# CC2340R5 register map
File version: 1.0
CPU: CM0P 1.0, other endian, MPU, FPU, 3 interrupt priority bits
Registers are 32-bit, read-write, reset 0x0 unless marked. A register's access mark holds for its fields unless they carry their own. Offsets are from the block's base; [hi:lo] are bit positions; {n}, {i} and the like mark numbered series.

## CLKCTL — This component is the clock controller. Here SW can turn on and off IP clocks and read IP and system clock status.
Base 0x40020000
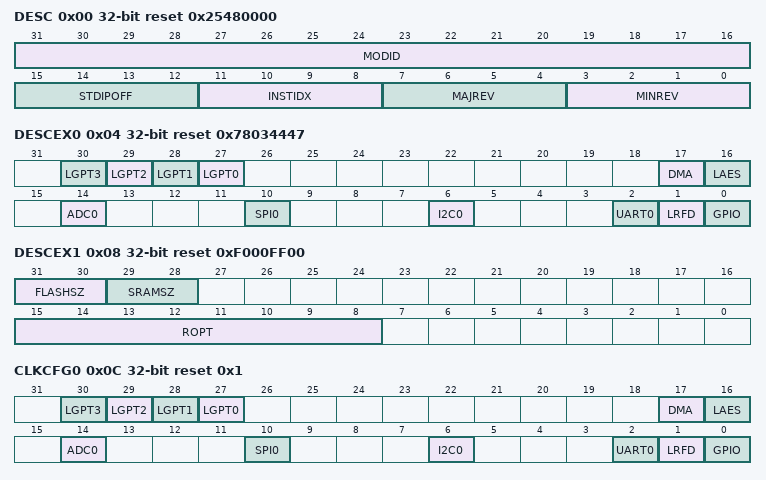
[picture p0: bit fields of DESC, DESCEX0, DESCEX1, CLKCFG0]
0x00 DESC reset 0x25480000 — Description Register. This register provides IP module ID, revision information, instance index and standard MMR registers offset.
  [31:16] MODID ro — [31:16] Module identifier used to uniquely identify this IP.
  [15:12] STDIPOFF ro — [15:12] Standard IP MMR block offset. Standard IP MMRs are the set of from aggregated IRQ registers till DTB. 0: Standard IP MMRs do not exist 0x1-0xF: Standard IP MMRs begin at offset of (64*STDIPOFF from the base IP address)
  [11:8] INSTIDX ro — [11:8] IP Instance ID number. If multiple instances of IP exist in the device, this field can identify the instance number (0-15).
  [7:4] MAJREV ro — [7:4] Major revision of IP 0-15
  [3:0] MINREV ro — [3:0] Minor revision of IP 0-15.
0x04 DESCEX0 reset 0x78034447 — Extended Description Register 0. This register shows SVT IP availability, HW features and memory size configuration.
  [all] fields
    1=IP_AVAIL (IP is available); 0=IP_UNAVAIL (IP is unavailable)
  [n+27] LGPT{n} ro (n=0..3) — [{n+27}:{n+27}] IP status on device
  [17] DMA ro — [17:17] IP status on device
  [16] LAES ro — [16:16] IP status on device
  [14] ADC0 ro — [14:14] IP status on device
  [10] SPI0 ro — [10:10] IP status on device
  [6] I2C0 ro — [6:6] IP status on device
  [2] UART0 ro — [2:2] IP status on device
  [1] LRFD ro — [1:1] IP status on device
  [0] GPIO ro — [0:0] IP status on device
0x08 DESCEX1 reset 0xF000FF00 — Extended Description Register 1. This register shows SVT IP availability, HW features and memory size configuration.
  [31:30] FLASHSZ ro — [31:30] System flash availability
    3=SZ3 (Flash size set to level 3 (Max size)); 2=SZ2 (Flash size set to level 2); 1=SZ1 (Flash size set to level 1); 0=SZ0 (Flash size set to level 0 (Min size))
  [29:28] SRAMSZ ro — [29:28] System SRAM availability
    3=SZ3 (SRAM size set to level 3 (Max size)); 2=SZ2 (SRAM size set to level 2); 1=SZ1 (SRAM size set to level 1); 0=SZ0 (SRAM size set to level 0 (Min size))
  [15:8] ROPT ro — [15:8] System radio feature availability
    255=MAX (All features available)
0x0C CLKCFG0 reset 0x1 — Clock Configuration Register 0. This register shows the IP clock configuration for the system. The configuration is updated through CLKENSET0 and CLKENCLR0.
  [all] fields
    1=CLK_EN (Clock is enabled); 0=CLK_DIS (Clock is disabled)
  [n+27] LGPT{n} ro (n=0..3) — [{n+27}:{n+27}] IP clock configuration
  [17] DMA ro — [17:17] IP clock configuration
  [16] LAES ro — [16:16] IP clock configuration
  [14] ADC0 ro — [14:14] IP clock configuration
  [10] SPI0 ro — [10:10] IP clock configuration
  [6] I2C0 ro — [6:6] IP clock configuration
  [2] UART0 ro — [2:2] IP clock configuration
  [1] LRFD ro — [1:1] IP clock configuration
  [0] GPIO ro — [0:0] IP clock configuration
0x10 CLKCFG1 — Clock Configuration Register 1. This register shows the IP clock configuration for the system. The configuration is updated through CLKENSET1 and CLKENCLR1.
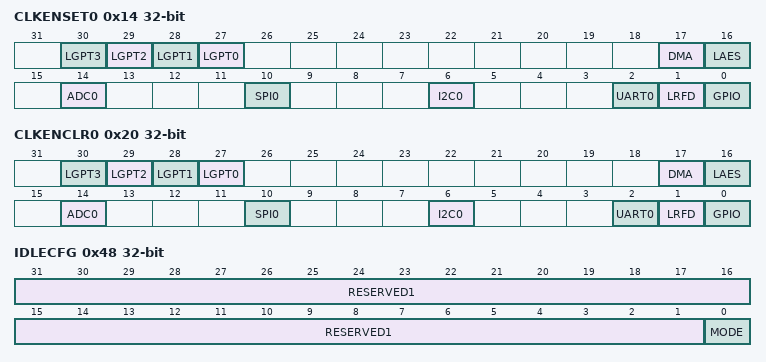
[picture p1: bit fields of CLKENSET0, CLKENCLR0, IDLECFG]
0x14 CLKENSET0 — Clock Enable Set Register 0. This register enables IP clocks in the system. Used to set the corresponding fields in CLKCFG0 to 1.
  [all] fields
    1=CLK_SET (Set IP clock enable); 0=CLK_UNCHGD (IP clock enable is unchanged)
  [n+27] LGPT{n} wo (n=0..3) — [{n+27}:{n+27}] Configure IP clock enable
  [17] DMA wo — [17:17] Configure IP clock enable
  [16] LAES wo — [16:16] Configure IP clock enable
  [14] ADC0 wo — [14:14] Configure IP clock enable
  [10] SPI0 wo — [10:10] Configure IP clock enable
  [6] I2C0 wo — [6:6] Configure IP clock enable
  [2] UART0 wo — [2:2] Configure IP clock enable
  [1] LRFD wo — [1:1] Configure IP clock enable
  [0] GPIO wo — [0:0] Configure IP clock enable
0x18 CLKENSET1 — Clock Enable Set Register 1. This register enables IP clocks in the system. Used to set the corresponding fields in CLKCFG1 to 1.
0x20 CLKENCLR0 — Clock Enable Clear Register 0. This register disables IP clocks in the system. Used to clear the corresponding fields in CLKCFG0 to 0.
  [all] fields
    1=CLK_CLR (Clear IP clock enable); 0=CLK_UNCHGD (IP clock enable is unchanged)
  [n+27] LGPT{n} wo (n=0..3) — [{n+27}:{n+27}] Configure IP clock enable
  [17] DMA wo — [17:17] Configure IP clock enable
  [16] LAES wo — [16:16] Configure IP clock enable
  [14] ADC0 wo — [14:14] Configure IP clock enable
  [10] SPI0 wo — [10:10] Configure IP clock enable
  [6] I2C0 wo — [6:6] Configure IP clock enable
  [2] UART0 wo — [2:2] Configure IP clock enable
  [1] LRFD wo — [1:1] Configure IP clock enable
  [0] GPIO wo — [0:0] Configure IP clock enable
0x24 CLKENCLR1 — Clock Enable Clear Register 1. This register disables IP clocks in the system. Used to clear the corresponding fields in CLKCFG1 to 0.
0x3C STBYPTR — Internal. Only to be used through TI provided API.
  [31:0] VAL — [31:0] Internal. Only to be used through TI provided API.
    0=MIN (Internal. Only to be used through TI provided API.)
0x48 IDLECFG — Internal. Only to be used through TI provided API.
  [31:1] RESERVED1 ro — [31:1] Internal. Only to be used through TI provided API.
  [0] MODE — [0:0] Internal. Only to be used through TI provided API.
    1=LDO_OFF (Internal. Only to be used through TI provided API.); 0=LDO_ON (Internal. Only to be used through TI provided API.)
